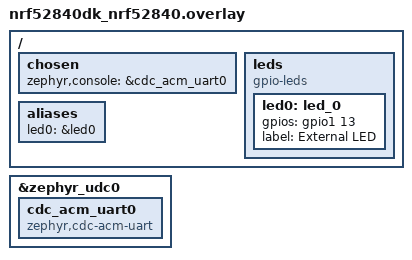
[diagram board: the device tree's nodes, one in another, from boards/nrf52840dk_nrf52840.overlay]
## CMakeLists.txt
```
cmake_minimum_required(VERSION 3.20.0)
find_package(Zephyr REQUIRED HINTS $ENV{ZEPHYR_BASE})

project(fth_adc_batterymonitor)

target_sources(app PRIVATE 
    src/main.c
    src/battery.c
    src/ble_service.c
    )
```

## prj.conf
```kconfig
CONFIG_GPIO=y
CONFIG_ADC=y

CONFIG_SERIAL=y
CONFIG_CONSOLE=y
CONFIG_UART_CONSOLE=y

CONFIG_USB_DEVICE_STACK=y
CONFIG_USB_CDC_ACM=y
CONFIG_USB_DEVICE_INITIALIZE_AT_BOOT=y

CONFIG_CLOCK_CONTROL_NRF_K32SRC_RC=y
CONFIG_CLOCK_CONTROL_NRF_K32SRC_XTAL=n

CONFIG_BT=y
CONFIG_BT_PERIPHERAL=y
CONFIG_BT_DEVICE_NAME="FTH_E73_BAT"
CONFIG_BT_DEVICE_APPEARANCE=833
CONFIG_BT_MAX_CONN=1

CONFIG_MAIN_STACK_SIZE=2048
CONFIG_SYSTEM_WORKQUEUE_STACK_SIZE=2048

CONFIG_PM=y
CONFIG_PM_DEVICE=y
CONFIG_PM_DEVICE_RUNTIME=y
```

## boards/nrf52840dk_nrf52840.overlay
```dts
/ {
    chosen {
        zephyr,console = &cdc_acm_uart0;
    };

    leds {
        compatible = "gpio-leds";

        led0: led_0 {
            gpios = <&gpio1 13 GPIO_ACTIVE_HIGH>;
            label = "External LED";
        };
    };

    aliases {
        led0 = &led0;
    };
};

&zephyr_udc0 {
    cdc_acm_uart0: cdc_acm_uart0 {
        compatible = "zephyr,cdc-acm-uart";
    };
};
```

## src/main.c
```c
#include <zephyr/kernel.h>
#include <zephyr/device.h>
#include <zephyr/drivers/gpio.h>
#include <zephyr/usb/usb_device.h>
#include <zephyr/sys/printk.h>
#include <zephyr/bluetooth/bluetooth.h>
#include <zephyr/bluetooth/gap.h>
#include <zephyr/bluetooth/conn.h>

#include "ble_service.h"

#include "battery.h"

#define PERIODIC_WAKEUP_SECONDS 60

static const struct gpio_dt_spec led = GPIO_DT_SPEC_GET(DT_ALIAS(led0), gpios);

static const struct bt_data ad[] = {
    BT_DATA_BYTES(BT_DATA_FLAGS, BT_LE_AD_GENERAL | BT_LE_AD_NO_BREDR),
    BT_DATA(BT_DATA_NAME_COMPLETE, CONFIG_BT_DEVICE_NAME,
            sizeof(CONFIG_BT_DEVICE_NAME) - 1),
};

int main(void)
{
    int err;
    int32_t battery_mv;
    uint8_t battery_percent;

    usb_enable(NULL);
    k_sleep(K_MSEC(1000));

    printk("\nFTH E73 Battery Monitor started\n");

    if (device_is_ready(led.port))
    {
        gpio_pin_configure_dt(&led, GPIO_OUTPUT_INACTIVE);
    }

    err = battery_init();
    if (err)
    {
        printk("Battery init failed: %d\n", err);
        return 0;
    }

    printk("Battery ADC initialized\n");

    err = bt_enable(NULL);
    if (err)
    {
        printk("Bluetooth init failed: %d\r\n", err);
        return 0;
    }

    printk("Bluetooth initialized\r\n");

    ble_service_init();

    err = bt_le_adv_start(BT_LE_ADV_CONN_FAST_1, ad, ARRAY_SIZE(ad), NULL, 0);
    if (err)
    {
        printk("Advertising failed: %d\r\n", err);
        return 0;
    }

    printk("Advertising as %s\r\n", CONFIG_BT_DEVICE_NAME);

    while (1)
{
    err = battery_read_mv(&battery_mv);

    if (err == 0)
    {
        battery_percent = battery_percent_from_mv(battery_mv);

        printk("Battery: %ld mV, %u %%\r\n",
               (long)battery_mv,
               battery_percent);

        err = ble_service_notify_battery(battery_percent, battery_mv);
        if (err == 0)
        {
            printk("BLE battery notify sent\r\n");
        }

        if (device_is_ready(led.port))
        {
            gpio_pin_toggle_dt(&led);
        }
    }
    else
    {
        printk("Battery read failed: %d\r\n", err);
    }

    k_sleep(K_SECONDS(PERIODIC_WAKEUP_SECONDS));
}
}
```

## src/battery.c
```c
#include "battery.h"

#include <zephyr/kernel.h>
#include <zephyr/device.h>
#include <zephyr/drivers/adc.h>
#include <zephyr/sys/printk.h>

#define ADC_NODE        DT_NODELABEL(adc)
#define ADC_CHANNEL_ID  3
#define ADC_RESOLUTION  12
#define ADC_GAIN        ADC_GAIN_1_6
#define ADC_REFERENCE   ADC_REF_INTERNAL
#define ADC_ACQ_TIME    ADC_ACQ_TIME_DEFAULT

#define BATTERY_DIVIDER_MULTIPLIER 11

static const struct device *adc_dev = DEVICE_DT_GET(ADC_NODE);
static int16_t sample_buffer;

static struct adc_channel_cfg channel_cfg = {
    .gain = ADC_GAIN,
    .reference = ADC_REFERENCE,
    .acquisition_time = ADC_ACQ_TIME,
    .channel_id = ADC_CHANNEL_ID,
#if defined(CONFIG_ADC_CONFIGURABLE_INPUTS)
    .input_positive = SAADC_CH_PSELP_PSELP_AnalogInput3, // P0.05 = AIN3
#endif
};

int battery_init(void)
{
    if (!device_is_ready(adc_dev)) {
        printk("ADC device not ready\n");
        return -ENODEV;
    }

    int err = adc_channel_setup(adc_dev, &channel_cfg);
    if (err) {
        printk("ADC channel setup failed: %d\n", err);
        return err;
    }

    return 0;
}

int battery_read_mv(int32_t *battery_mv)
{
    int err;
    int32_t total_mv = 0;

    const struct adc_sequence sequence = {
        .channels = BIT(ADC_CHANNEL_ID),
        .buffer = &sample_buffer,
        .buffer_size = sizeof(sample_buffer),
        .resolution = ADC_RESOLUTION,
    };

    for (int i = 0; i < 32; i++) {
        err = adc_read(adc_dev, &sequence);
        if (err) {
            return err;
        }

        int32_t adc_mv = sample_buffer;

        err = adc_raw_to_millivolts(
            adc_ref_internal(adc_dev),
            ADC_GAIN,
            ADC_RESOLUTION,
            &adc_mv
        );

        if (err) {
            return err;
        }

        total_mv += adc_mv;
        k_sleep(K_MSEC(5));
    }

    int32_t avg_adc_mv = total_mv / 32;

    *battery_mv =
        (((avg_adc_mv * BATTERY_DIVIDER_MULTIPLIER) + 5) / 10) * 10;

    return 0;
}

uint8_t battery_percent_from_mv(int32_t mv)
{
    if (mv >= 4200) return 100;
    if (mv >= 4100) return 90;
    if (mv >= 4000) return 80;
    if (mv >= 3900) return 70;
    if (mv >= 3800) return 60;
    if (mv >= 3700) return 50;
    if (mv >= 3600) return 30;
    if (mv >= 3500) return 20;
    if (mv >= 3400) return 10;
    if (mv >= 3300) return 5;

    return 0;
}
```

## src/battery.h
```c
#ifndef BATTERY_H
#define BATTERY_H

#include <stdint.h>

int battery_init(void);
int battery_read_mv(int32_t *battery_mv);
uint8_t battery_percent_from_mv(int32_t mv);

#endif
```

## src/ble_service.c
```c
#include "ble_service.h"

#include <zephyr/kernel.h>
#include <zephyr/bluetooth/bluetooth.h>
#include <zephyr/bluetooth/gatt.h>
#include <zephyr/sys/printk.h>

static bool notify_enabled;

static void ccc_cfg_changed(const struct bt_gatt_attr *attr, uint16_t value)
{
    notify_enabled = (value == BT_GATT_CCC_NOTIFY);
    printk("Battery notify %s\r\n", notify_enabled ? "enabled" : "disabled");
}

BT_GATT_SERVICE_DEFINE(battery_svc,
    BT_GATT_PRIMARY_SERVICE(BT_UUID_DECLARE_128(
        0x10, 0x00, 0x00, 0x00, 0x5f, 0x9b, 0x4f, 0x7a,
        0x9b, 0x3a, 0x7e, 0x01, 0x00, 0x00, 0xab, 0xcd)),

    BT_GATT_CHARACTERISTIC(BT_UUID_DECLARE_128(
        0x10, 0x01, 0x00, 0x00, 0x5f, 0x9b, 0x4f, 0x7a,
        0x9b, 0x3a, 0x7e, 0x01, 0x00, 0x00, 0xab, 0xcd),
        BT_GATT_CHRC_NOTIFY,
        BT_GATT_PERM_NONE,
        NULL, NULL, NULL),

    BT_GATT_CCC(ccc_cfg_changed, BT_GATT_PERM_READ | BT_GATT_PERM_WRITE)
);

int ble_service_init(void)
{
    notify_enabled = false;
    return 0;
}

int ble_service_notify_battery(uint8_t percent, int32_t battery_mv)
{
    uint8_t data[4];
    uint8_t alarm_flags = 0;

    if (!notify_enabled) {
        return -EACCES;
    }

    if (battery_mv <= 3600) {
        alarm_flags |= BIT(0);   // low battery
    }

    if (battery_mv <= 3400) {
        alarm_flags |= BIT(1);   // critical battery
    }

    data[0] = percent;
    data[1] = (uint8_t)(battery_mv & 0xFF);
    data[2] = (uint8_t)((battery_mv >> 8) & 0xFF);
    data[3] = alarm_flags;

    return bt_gatt_notify(NULL, &battery_svc.attrs[1], data, sizeof(data));
}
```

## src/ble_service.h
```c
#ifndef BLE_SERVICE_H
#define BLE_SERVICE_H

#include <stdint.h>
#include <stddef.h>

int ble_service_init(void);
int ble_service_notify_battery(uint8_t percent, int32_t battery_mv);

#endif
```
